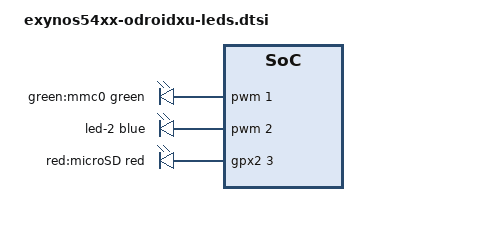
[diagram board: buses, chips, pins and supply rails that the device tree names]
#include <dt-bindings/gpio/gpio.h>
#include <dt-bindings/leds/common.h>
/ {
	led-controller-1 {
		compatible = "pwm-leds";
		led-1 {
			label = "green:mmc0";
			function = LED_FUNCTION_DISK_ACTIVITY;
			color = <LED_COLOR_ID_GREEN>;
			pwms = <&pwm 1 2000000 0>;
			pwm-names = "pwm1";
			max-brightness = <127>;
			linux,default-trigger = "mmc0";
		};
		led-2 {
			function = LED_FUNCTION_HEARTBEAT;
			color = <LED_COLOR_ID_BLUE>;
			pwms = <&pwm 2 2000000 0>;
			pwm-names = "pwm2";
			max-brightness = <255>;
			linux,default-trigger = "heartbeat";
		};
	};
	led-controller-2 {
		compatible = "gpio-leds";
		led-3 {
			label = "red:microSD";
			function = LED_FUNCTION_DISK_ACTIVITY;
			color = <LED_COLOR_ID_RED>;
			gpios = <&gpx2 3 GPIO_ACTIVE_HIGH>;
			default-state = "off";
			linux,default-trigger = "mmc1";
		};
	};
};
